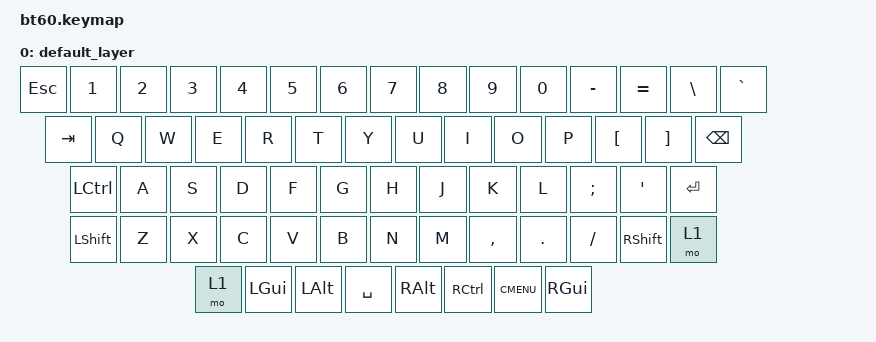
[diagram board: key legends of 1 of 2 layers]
#include <behaviors.dtsi>
#include <dt-bindings/zmk/keys.h>
#include <dt-bindings/zmk/bt.h>

/ {
	keymap {
		compatible = "zmk,keymap";

		default_layer {
				// ------------------------------------------------------------------------------------------
				// | ESC |  1  |  2  |  3  |  4  |  5  |  6  |  7  |  8  |  9  |  0  |  -  |  =  |  \  | `  |
				// | TAB  |  Q  |  W  |  E  |  R  |  T  |  Y  |  U  |  I  |  O  |  P  |  [  |  ]  |  BKSP   |
				// | CTRL  |  A  |  S  |  D  |  F  |  G  |  H  |  J  |  K  |  L  |  ;  |  '  |     ENTER    |
				// |  SHIFT    |  Z  |  X  |  C  |  V  |  B  |  N  |  M  |  ,  |  .  | /   |   SHIFT  |  1  |
				// |  CTL  |  WIN  |  ALT  |            SPACE               | ALT |     |  MENU    |  CTRL    |
				// ------------------------------------------------------------------------------------------
			bindings = <
				&kp ESC &kp N1 &kp N2 &kp N3 &kp N4 &kp N5 &kp N6 &kp N7 &kp  N8   &kp  N9 &kp  N0  &kp MINUS &kp EQUAL &kp BSLH &kp GRAVE
				&kp TAB  &kp Q  &kp W  &kp E  &kp R  &kp T  &kp Y  &kp U  &kp  I    &kp  O  &kp  P   &kp LBKT &kp RBKT  &kp BSPC
				&kp LCTRL  &kp A  &kp S  &kp D  &kp F  &kp G  &kp H  &kp J  &kp  K    &kp  L  &kp SEMI &kp SQT           &kp RET
				&kp LSHFT  &kp Z  &kp X  &kp C  &kp V  &kp B  &kp N  &kp M  &kp COMMA &kp DOT &kp FSLH &kp RSHFT   &mo 1
				&mo 1 &kp LGUI &kp LALT            &kp SPACE                          &kp RALT &kp RCTRL &kp K_CMENU &kp RGUI
			>;
			sensor-bindings = <&inc_dec_kp C_VOL_UP C_VOL_DN>;
		};
		raise {
			bindings = <
				&kp DEL &kp F1 &kp F2 &kp F3 &kp F4 &kp F5 &kp F6 &kp F7 &kp  F8   &kp  F9 &kp  F10  &kp F11 &kp F12   &kp C_SLEEP
				&trans &trans &kp UP &trans &trans &trans &trans &trans &kp PSCRN &trans &trans &trans &trans &sys_reset 
				&trans    &kp C_VOL_DN &kp C_VOL_UP &kp C_MUTE &trans &trans &trans &kp LEFT &kp DOWN &kp UP &kp RIGHT  &trans   &bootloader
				&trans  &kp C_PP &kp C_PREV &kp C_NEXT &trans &trans &trans &trans &trans &trans &trans  &trans &trans
				&bt BT_PRV &bt BT_NXT  &bt BT_CLR              &trans                            &trans   &trans   &trans &trans
			>;
			sensor-bindings = <&inc_dec_kp C_VOL_UP C_VOL_DN>;
		};
	};
};
